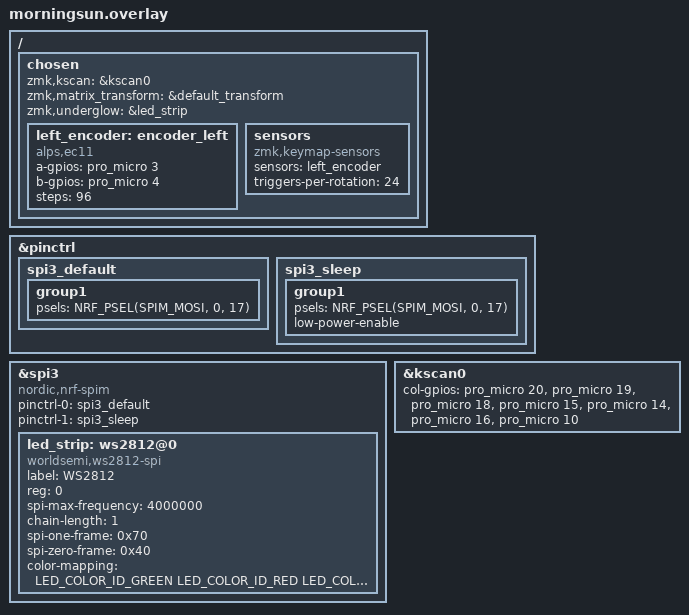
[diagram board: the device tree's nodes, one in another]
/*
 * Copyright (c) 2020 Pete Johanson
 *
 * SPDX-License-Identifier: MIT
 */

#include "endless.dtsi"
#include <dt-bindings/zmk/keys.h>
#include <dt-bindings/zmk/bt.h>
#include <dt-bindings/zmk/rgb.h>
#include <dt-bindings/led/led.h>

/ {
    chosen {
        zmk,kscan = &kscan0;
        zmk,matrix_transform = &default_transform;
        zmk,underglow = &led_strip;

        left_encoder: encoder_left {
		    compatible = "alps,ec11";
            a-gpios = <&pro_micro 3 (GPIO_ACTIVE_HIGH | GPIO_PULL_UP)>;
            b-gpios = <&pro_micro 4 (GPIO_ACTIVE_HIGH | GPIO_PULL_UP)>;
            steps = <96>;
		    status = "disabled";
        };
        sensors: sensors {
    		compatible = "zmk,keymap-sensors";
	    	sensors = <&left_encoder>;
            triggers-per-rotation = <24>;
        };
    };
};

&pinctrl {
	spi3_default: spi3_default {
		group1 {
			psels = <NRF_PSEL(SPIM_MOSI, 0, 17)>;
		};
	};

	spi3_sleep: spi3_sleep {
		group1 {
			psels = <NRF_PSEL(SPIM_MOSI, 0, 17)>;
			low-power-enable;
		};
	};
};


&spi3 {
	compatible = "nordic,nrf-spim";
	status = "okay";

	pinctrl-0 = <&spi3_default>;
	pinctrl-1 = <&spi3_sleep>;
	pinctrl-names = "default", "sleep";

	led_strip: ws2812@0 {
		compatible = "worldsemi,ws2812-spi";
		label = "WS2812";

		/* SPI */
		reg = <0>; /* ignored, but necessary for SPI bindings */
		spi-max-frequency = <4000000>;

		/* WS2812 */
		chain-length = <1>; /* arbitrary; change at will */
		spi-one-frame = <0x70>;
		spi-zero-frame = <0x40>;

		color-mapping = <LED_COLOR_ID_GREEN LED_COLOR_ID_RED LED_COLOR_ID_BLUE>;
	};
};

&kscan0 {
    col-gpios
        = <&pro_micro 20 GPIO_ACTIVE_HIGH>
        , <&pro_micro 19 GPIO_ACTIVE_HIGH>
        , <&pro_micro 18 GPIO_ACTIVE_HIGH>
        , <&pro_micro 15 GPIO_ACTIVE_HIGH>
        , <&pro_micro 14 GPIO_ACTIVE_HIGH>
        , <&pro_micro 16 GPIO_ACTIVE_HIGH>
        , <&pro_micro 10 GPIO_ACTIVE_HIGH>
        ;
};

&left_encoder {
	status = "okay";
};
